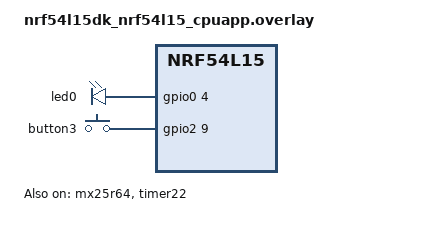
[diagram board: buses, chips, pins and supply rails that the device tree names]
/*
 * Copyright (c) 2026 Nordic Semiconductor ASA
 *
 * SPDX-License-Identifier: LicenseRef-Nordic-5-Clause
 */

/ {
	aliases {
		dut-flash = &mx25r64;
	};
};

&led0 {
	gpios = <&gpio0 4 GPIO_ACTIVE_HIGH>;
};

&button3 {
	gpios = <&gpio2 9 GPIO_ACTIVE_HIGH>;
};

&mx25r64 {
	status = "okay";
	spi-max-frequency = <DT_FREQ_M(8)>;
};

tst_timer: &timer22 {
	status = "okay";
};

&uart20 {
	zephyr,pm-device-runtime-auto;
	disable-rx;
};

&spi00 {
	zephyr,pm-device-runtime-auto;
};
